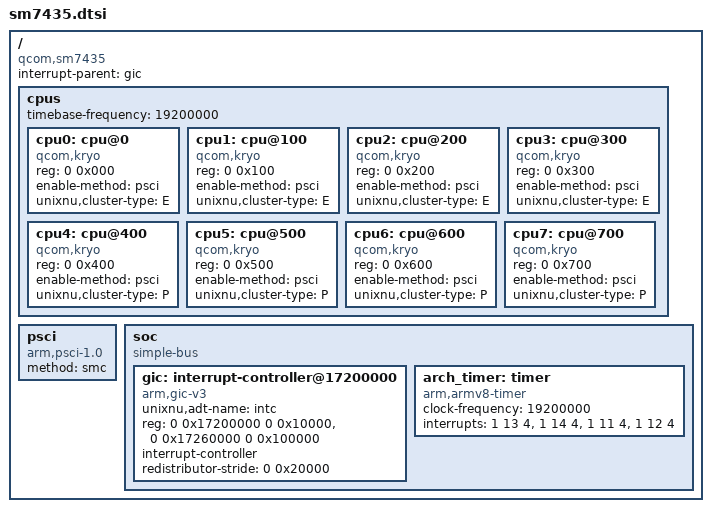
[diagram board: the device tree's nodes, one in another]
// SPDX-License-Identifier: BSD-3-Clause
// Qualcomm SM7435 (Parrot) CPU/GICv3/PSCI subset for UniXNU.
//
// Hardware source: LineageOS/android_kernel_xiaomi_sm7435-devicetrees
// qcom/parrot.dtsi at 849a8a76b0959f7e7c12eb67081591248b2f8e7b.
// Bootloader FDT cross-check: UniXNU-Dizi-Ruan/data/dizi-fdt-observed.json.
//
// PREPARATORY ONLY: no successful XNU/DarwinBoot/SMP test on dizi yet.
// Do not borrow SM8550 clock, GPU, SMMU or PMIC addresses.
/ {
    compatible = "qcom,sm7435";
    #address-cells = <2>;
    #size-cells = <2>;
    interrupt-parent = <&gic>;

    cpus {
        #address-cells = <2>;
        #size-cells = <0>;
        timebase-frequency = <19200000>;

        // Original Parrot Linux DT: 4 efficiency + 4 performance CPUs.
        // MPIDR affinity values below are DT-derived, not device-tested by XNU.
        cpu0: cpu@0   { device_type = "cpu"; compatible = "qcom,kryo"; reg = <0 0x000>; enable-method = "psci"; unixnu,cluster-type = "E"; };
        cpu1: cpu@100 { device_type = "cpu"; compatible = "qcom,kryo"; reg = <0 0x100>; enable-method = "psci"; unixnu,cluster-type = "E"; };
        cpu2: cpu@200 { device_type = "cpu"; compatible = "qcom,kryo"; reg = <0 0x200>; enable-method = "psci"; unixnu,cluster-type = "E"; };
        cpu3: cpu@300 { device_type = "cpu"; compatible = "qcom,kryo"; reg = <0 0x300>; enable-method = "psci"; unixnu,cluster-type = "E"; };
        cpu4: cpu@400 { device_type = "cpu"; compatible = "qcom,kryo"; reg = <0 0x400>; enable-method = "psci"; unixnu,cluster-type = "P"; };
        cpu5: cpu@500 { device_type = "cpu"; compatible = "qcom,kryo"; reg = <0 0x500>; enable-method = "psci"; unixnu,cluster-type = "P"; };
        cpu6: cpu@600 { device_type = "cpu"; compatible = "qcom,kryo"; reg = <0 0x600>; enable-method = "psci"; unixnu,cluster-type = "P"; };
        cpu7: cpu@700 { device_type = "cpu"; compatible = "qcom,kryo"; reg = <0 0x700>; enable-method = "psci"; unixnu,cluster-type = "P"; };
    };

    psci {
        compatible = "arm,psci-1.0";
        method = "smc";
    };

    soc {
        compatible = "simple-bus";
        #address-cells = <2>;
        #size-cells = <2>;
        ranges;

        gic: interrupt-controller@17200000 {
            compatible = "arm,gic-v3";
            unixnu,adt-name = "intc";
            reg = <0 0x17200000 0 0x10000>,
                  <0 0x17260000 0 0x100000>;
            #interrupt-cells = <3>;
            #address-cells = <0>;
            interrupt-controller;
            redistributor-stride = <0 0x20000>;
        };

        arch_timer: timer {
            compatible = "arm,armv8-timer";
            clock-frequency = <19200000>;
            // Parrot timer PPIs 13,14,11,12; PPI11 -> virtual timer INTID27.
            interrupts = <1 13 4>, <1 14 4>, <1 11 4>, <1 12 4>;
        };
    };
};
